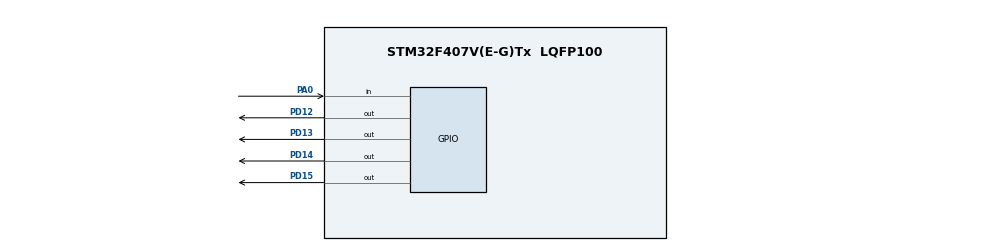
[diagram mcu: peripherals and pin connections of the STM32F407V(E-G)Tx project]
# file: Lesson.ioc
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Mcu.Family=STM32F4
Mcu.Name=STM32F407V(E-G)Tx
Mcu.Package=LQFP100
NVIC.PriorityGroup=NVIC_PRIORITYGROUP_4
PA0-WKUP.Signal=GPIO_Input
PD12.Signal=GPIO_Output
PD13.Signal=GPIO_Output
PD14.Signal=GPIO_Output
PD15.Signal=GPIO_Output
PH0-OSC_IN.Mode=HSE-External-Oscillator
PH0-OSC_IN.Signal=RCC_OSC_IN
PH1-OSC_OUT.Mode=HSE-External-Oscillator
PH1-OSC_OUT.Signal=RCC_OSC_OUT
ProjectManager.HeapSize=0x200
ProjectManager.StackSize=0x400
ProjectManager.TargetToolchain=MDK-ARM V5
RCC.48MHZClocksFreq_Value=84000000
RCC.AHBFreq_Value=168000000
RCC.APB1CLKDivider=RCC_HCLK_DIV4
RCC.APB1Freq_Value=42000000
RCC.APB1TimFreq_Value=84000000
RCC.APB2CLKDivider=RCC_HCLK_DIV2
RCC.APB2Freq_Value=84000000
RCC.APB2TimFreq_Value=168000000
RCC.CortexFreq_Value=168000000
RCC.HCLKFreq_Value=168000000
RCC.HSE_VALUE=8000000
RCC.HSI_VALUE=16000000
RCC.LSE_VALUE=32768
RCC.PLLM=4
RCC.PLLN=168
RCC.PLLSourceVirtual=RCC_PLLSOURCE_HSE
RCC.SYSCLKFreq_VALUE=168000000
RCC.SYSCLKSource=RCC_SYSCLKSOURCE_PLLCLK
RCC.VCOOutputFreq_Value=336000000
board=custom

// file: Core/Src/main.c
/* USER CODE BEGIN Header */
/**
  ******************************************************************************
  * @file           : main.c
  * @brief          : Main program body
  ******************************************************************************
  * @attention
  *
  * <h2><center>&copy; Copyright (c) 2021 STMicroelectronics.
  * All rights reserved.</center></h2>
  *
  * This software component is licensed by ST under BSD 3-Clause license,
  * the "License"; You may not use this file except in compliance with the
  * License. You may obtain a copy of the License at:
  *                        opensource.org/licenses/BSD-3-Clause
  *
  ******************************************************************************
  */
/* USER CODE END Header */
#include "main.h"

/* USER CODE BEGIN PM */
#define LED1_ON() LL_GPIO_SetOutputPin(GPIOD, LL_GPIO_PIN_12)
#define LED1_OFF() LL_GPIO_ResetOutputPin(GPIOD, LL_GPIO_PIN_12)
#define LED2_ON() LL_GPIO_SetOutputPin(GPIOD, LL_GPIO_PIN_13)
#define LED2_OFF() LL_GPIO_ResetOutputPin(GPIOD, LL_GPIO_PIN_13)
/* USER CODE END PM */

void SystemClock_Config(void);
static void MX_GPIO_Init(void);

int main(void)
{

  /* MCU Configuration--------------------------------------------------------*/

  /* Reset of all peripherals, Initializes the Flash interface and the Systick. */

  LL_APB2_GRP1_EnableClock(LL_APB2_GRP1_PERIPH_SYSCFG);
  LL_APB1_GRP1_EnableClock(LL_APB1_GRP1_PERIPH_PWR);

  NVIC_SetPriorityGrouping(NVIC_PRIORITYGROUP_4);

  /* System interrupt init*/
  /* SysTick_IRQn interrupt configuration */
  NVIC_SetPriority(SysTick_IRQn, NVIC_EncodePriority(NVIC_GetPriorityGrouping(),15, 0));

  /* Configure the system clock */
  SystemClock_Config();

  /* Initialize all configured peripherals */
  MX_GPIO_Init();

  /* Infinite loop */
  while (1)
  {

    /* USER CODE BEGIN 3 */
		if (LL_GPIO_IsInputPinSet(GPIOA, LL_GPIO_PIN_0 ) != 0)
		{
			LED1_ON();
			LL_mDelay(200);
			LED1_OFF();
			LL_mDelay(200);
			LED2_ON();
			LL_mDelay(200);
			LED2_OFF();
			LL_mDelay(200);
		}
  }
  /* USER CODE END 3 */
}

void SystemClock_Config(void)
{
  LL_FLASH_SetLatency(LL_FLASH_LATENCY_5);
  while(LL_FLASH_GetLatency()!= LL_FLASH_LATENCY_5)
  {
  }
  LL_PWR_SetRegulVoltageScaling(LL_PWR_REGU_VOLTAGE_SCALE1);
  LL_RCC_HSE_Enable();

   /* Wait till HSE is ready */
  while(LL_RCC_HSE_IsReady() != 1)
  {

  }
  LL_RCC_PLL_ConfigDomain_SYS(LL_RCC_PLLSOURCE_HSE, LL_RCC_PLLM_DIV_4, 168, LL_RCC_PLLP_DIV_2);
  LL_RCC_PLL_Enable();

   /* Wait till PLL is ready */
  while(LL_RCC_PLL_IsReady() != 1)
  {

  }
  LL_RCC_SetAHBPrescaler(LL_RCC_SYSCLK_DIV_1);
  LL_RCC_SetAPB1Prescaler(LL_RCC_APB1_DIV_4);
  LL_RCC_SetAPB2Prescaler(LL_RCC_APB2_DIV_2);
  LL_RCC_SetSysClkSource(LL_RCC_SYS_CLKSOURCE_PLL);

   /* Wait till System clock is ready */
  while(LL_RCC_GetSysClkSource() != LL_RCC_SYS_CLKSOURCE_STATUS_PLL)
  {

  }
  LL_Init1msTick(168000000);
  LL_SetSystemCoreClock(168000000);
}

static void MX_GPIO_Init(void)
{
  LL_GPIO_InitTypeDef GPIO_InitStruct = {0};

  /* GPIO Ports Clock Enable */
  LL_AHB1_GRP1_EnableClock(LL_AHB1_GRP1_PERIPH_GPIOH);
  LL_AHB1_GRP1_EnableClock(LL_AHB1_GRP1_PERIPH_GPIOA);
  LL_AHB1_GRP1_EnableClock(LL_AHB1_GRP1_PERIPH_GPIOD);

  /**/
  LL_GPIO_ResetOutputPin(GPIOD, LL_GPIO_PIN_12|LL_GPIO_PIN_13|LL_GPIO_PIN_14|LL_GPIO_PIN_15);

  /**/
  GPIO_InitStruct.Pin = LL_GPIO_PIN_0;
  GPIO_InitStruct.Mode = LL_GPIO_MODE_INPUT;
  GPIO_InitStruct.Pull = LL_GPIO_PULL_NO;
  LL_GPIO_Init(GPIOA, &GPIO_InitStruct);

  /**/
  GPIO_InitStruct.Pin = LL_GPIO_PIN_12|LL_GPIO_PIN_13|LL_GPIO_PIN_14|LL_GPIO_PIN_15;
  GPIO_InitStruct.Mode = LL_GPIO_MODE_OUTPUT;
  GPIO_InitStruct.Speed = LL_GPIO_SPEED_FREQ_LOW;
  GPIO_InitStruct.OutputType = LL_GPIO_OUTPUT_PUSHPULL;
  GPIO_InitStruct.Pull = LL_GPIO_PULL_NO;
  LL_GPIO_Init(GPIOD, &GPIO_InitStruct);

}

void Error_Handler(void)
{
  __disable_irq();
  while (1)
  {
  }
}

/************************ (C) COPYRIGHT STMicroelectronics *****END OF FILE****/
